# Cortex_M0PLUS register map
Vendor: ARM Ltd.; File version: 1.1
CPU: CM0PLUS r0p0, little endian, MPU, no FPU, vendor SysTick, 8 interrupt priority bits
Registers are 32-bit, read-write, reset 0x0 unless marked. A register's access mark holds for its fields unless they carry their own. Offsets are from the block's base; [hi:lo] are bit positions; {n}, {i} and the like mark numbered series; 'fields as' and 'values as' point back to an identical list.

## NVIC — Nested Vectored Interrupt Controller registers
Base 0xE000E100
0x00 NVIC_ISER0 reset not defined
0x00 NVIC_ISPR0 reset not defined
0x80 NVIC_ICER0 reset not defined
0x180 NVIC_ICPR0 reset not defined
0x200 NVIC_IABR0 reset not defined
{0x300+4i} NVIC_IPR{i} reset not defined (i=0..7)

## SysTick — System Timer registers
Base 0xE000E010
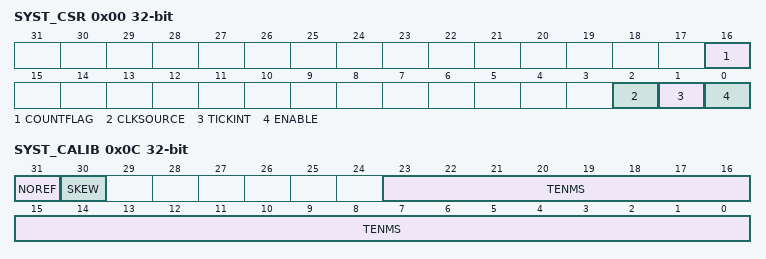
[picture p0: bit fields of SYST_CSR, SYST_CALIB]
0x00 SYST_CSR reset not defined
  [16] COUNTFLAG
    0=Not_counted_to_0; 1=Counted_to_0
  [2] CLKSOURCE
    0=External_clock; 1=Processor_clock
  [1] TICKINT
    0=Does_not_affect_exception_status; 1=Changes_exception_status
  [0] ENABLE
    0=Counter_disabled; 1=Counter_operating
0x04 SYST_RVR reset not defined
  [23:0] RELOAD
0x08 SYST_CVR reset not defined
  [23:0] CURRENT
0x0C SYST_CALIB reset not defined
  [31] NOREF
    0=Implemented; 1=Not_implemented
  [30] SKEW
    0=Exact; 1=Inexact
  [23:0] TENMS

## IOCON — IO configuration
Base 0x40044000
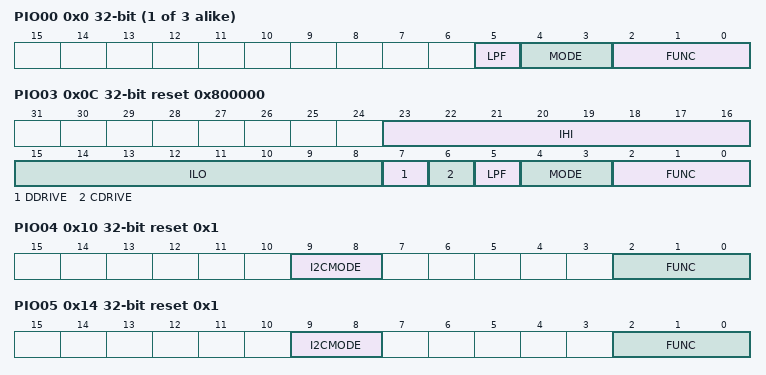
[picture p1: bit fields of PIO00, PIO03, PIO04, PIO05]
{0x0+4i} PIO{i:02} (i=0..2) — Digital I/O control for port 0 pins PIO_{i}
  [5] LPF — Low-pass filter
    0=DISABLED; 1=ENABLED
  [4:3] MODE — Selects function mode (on-chip pull-up/pull-down resistor control).
    0=INACTIVE (Inactive. Inactive (no pull-down/pull-up resistor enabled).); 1=PULL_DOWN (Pull-down. Pull-down resistor enabled.); 2=PULL_UP (Pull-up. Pull-up resistor enabled.); 3=REPEATER (Repeater. Repeater mode.)
  [2:0] FUNC — Selects pin function.
    {v}=ALT{v} (Alternative connection {v}.) (v=0..7)
0x0C PIO03 reset 0x800000 — Digital I/O control for port 0 pins PIO_3
  [23:16] IHI — Output high (asserted) value
  [15:8] ILO — Output low (deasserted) value
  [7] DDRIVE — Digital drive strength
    0=HIGH (High Drive (pad EHD0=0,EHD1=1)); 1=ULTRAHIGH (Ultra high Drive (pad EHD0=1,EHD1=1))
  [6] CDRIVE — Select pin output driver
    0=FIXED (Fixed voltage driver); 1=PROGRAMMABLE (Programmable current driver)
  [5] LPF — Low-pass filter
    0=DISABLED; 1=ENABLED
  [4:3] MODE — Selects function mode (on-chip pull-up/pull-down resistor control).
    values as PIO00.MODE
  [2:0] FUNC — Selects pin function.
    {v}=ALT{v} (Alternative connection {v}.) (v=0..7)
0x10 PIO04 reset 0x1 — Digital I/O control for port 0 pins PIO_4
  [9:8] I2CMODE — Selects I2C mode. Select I2C-bus standard/fast-mode I2CMODE = 00, default) or open-drain GPIO (4 mA) functionality (I2CMODE = 01) if the pin function is GPIO (FUNC = 000).
    0=STD_FAST_I2C (I2C-bus standard/fast-mode); 1=STD_I_O (open-drain GPIO (4 mA) functionality)
  [2:0] FUNC — Selects pin function.
    {v}=ALT{v} (Alternative connection {v}.) (v=0..7)
0x14 PIO05 reset 0x1 — Digital I/O control for port 0 pins PIO_5
  fields as PIO04
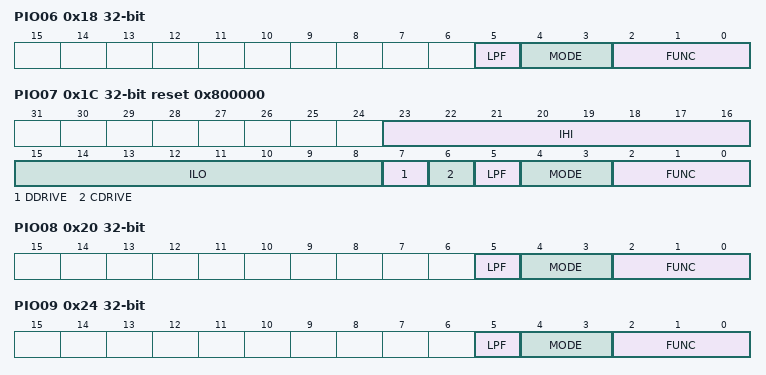
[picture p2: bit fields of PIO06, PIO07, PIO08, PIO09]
0x18 PIO06 — Digital I/O control for port 0 pins PIO_6
  fields as PIO00
0x1C PIO07 reset 0x800000 — Digital I/O control for port 0 pins PIO_7
  fields as PIO03
0x20 PIO08 — Digital I/O control for port 0 pins PIO_8
  fields as PIO00
0x24 PIO09 — Digital I/O control for port 0 pins PIO_9
  fields as PIO00
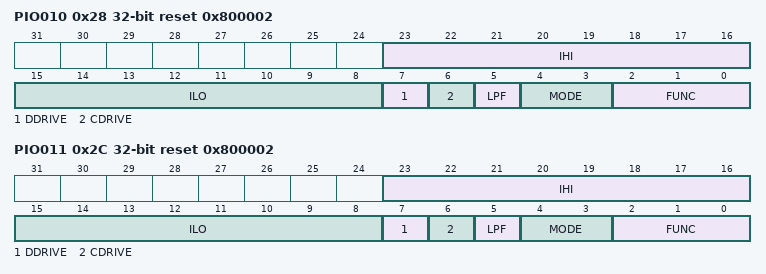
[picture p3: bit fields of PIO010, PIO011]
0x28 PIO010 reset 0x800002 — Digital I/O control for port 0 pins PIO_10
  fields as PIO03
0x2C PIO011 reset 0x800002 — Digital I/O control for port 0 pins PIO_11
  fields as PIO03

## RTC — Real time clock timer
Base 0x40054000
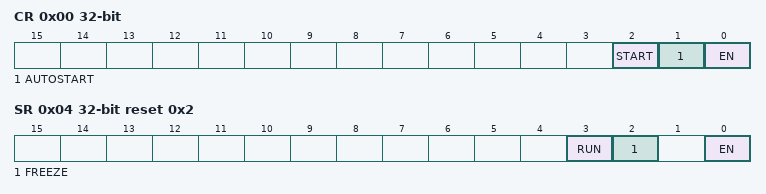
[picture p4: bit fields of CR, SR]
0x00 CR — RTC control register
  [2] START — Writing a 1 starts the countdown from the value stored in RTCSLEEPT until 0 is reached. Write 0 to clear. This bit is also cleared when the interrupt is asserted or a new value is written into the RTCSLEEPT register.
  [1] AUTOSTART — (1) Automatic timer start when value is written to RTCSLEEPT register, (0) manual start
  [0] EN — (1) Enable the RTC On/Off Timer, (0) disable
0x04 SR reset 0x2 — RTC status register
  [3] RUN ro — RTC timer is running
  [2] FREEZE ro — Asserted in the neighbourhood of edges on the internal tick clock. Values written to the RTCSLEEPT register during FREEZE=1 are delayed until after this conditions clears.
  [0] EN ro — RTC on/off timer enabled (1) or disabled (0)
0x08 CAL reset 0x8000 — RTC calibration value
  [15:0] CALIB — This value indicates the number of TFRO clock pulses in one tick.
0x0C SLEEPT — RTC Sleep time
  [23:0] SLEEPTIME — This value indicates the time to sleep in ticks.
0x10 VAL — Current RTC counter value
  [23:0] TIMEREMAIN ro — Current value (remaining time) of the countdown timer
0x14 IMIS — Interrupt mask register
  [0] IE — Software should set this bit to enable interrupt when the countdown is finished.
0x18 RIS — Raw Interrupt status register
  [0] RIS ro — This bit is 1 when the countdown has finished
0x1C MIS — Masked interrupt status register
  [0] MIS ro — This bit is 1 when the RTC countdown has finished and this interrupt is enabled.
0x20 ICR wo — Interrupt clear register
  [0] IC — Writing a 1 clears the countdown done interrupt
0x24 ACCSTAT — Access status register
  [0] READY ro — (0) RTC access not possible, (1) RTC access possible
0x30 TIME — RTC Time register
  [31:0] TIME — Current timer value
